# TM4C129ENCPDT register map
File version: 1.0
CPU: CORTEX_M4 1.0, other endian, MPU, FPU, 3 interrupt priority bits
Registers are 32-bit, read-write, reset 0x0 unless marked. A register's access mark holds for its fields unless they carry their own. Offsets are from the block's base; [hi:lo] are bit positions; {n}, {i} and the like mark numbered series.

## GPIO_PORTA_AHB — GPIO register offsets
Base 0x40058000
Same registers: GPIO_PORTB_AHB 0x40059000, GPIO_PORTC_AHB 0x4005A000, GPIO_PORTD_AHB 0x4005B000, GPIO_PORTE_AHB 0x4005C000, GPIO_PORTF_AHB 0x4005D000, GPIO_PORTG_AHB 0x4005E000, GPIO_PORTH_AHB 0x4005F000, GPIO_PORTJ_AHB 0x40060000, GPIO_PORTK 0x40061000, GPIO_PORTL 0x40062000, GPIO_PORTM 0x40063000, GPIO_PORTN 0x40064000, GPIO_PORTP 0x40065000, GPIO_PORTQ 0x40066000
0x3FC GPIO_DATA
0x400 GPIO_DIR — GPIO Direction
0x404 GPIO_IS — GPIO Interrupt Sense
0x408 GPIO_IBE — GPIO Interrupt Both Edges
0x40C GPIO_IEV — GPIO Interrupt Event
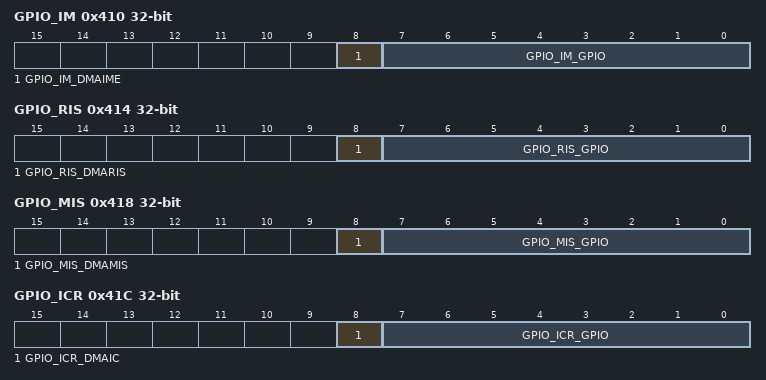
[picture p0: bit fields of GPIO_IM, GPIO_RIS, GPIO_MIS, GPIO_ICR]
0x410 GPIO_IM — GPIO Interrupt Mask
  [8] GPIO_IM_DMAIME — [8:8] GPIO uDMA Done Interrupt Mask Enable
  [7:0] GPIO_IM_GPIO — [7:0] GPIO Interrupt Mask Enable
0x414 GPIO_RIS — GPIO Raw Interrupt Status
  [8] GPIO_RIS_DMARIS — [8:8] GPIO uDMA Done Interrupt Raw Status
  [7:0] GPIO_RIS_GPIO — [7:0] GPIO Interrupt Raw Status
0x418 GPIO_MIS — GPIO Masked Interrupt Status
  [8] GPIO_MIS_DMAMIS — [8:8] GPIO uDMA Done Masked Interrupt Status
  [7:0] GPIO_MIS_GPIO — [7:0] GPIO Masked Interrupt Status
0x41C GPIO_ICR — GPIO Interrupt Clear
  [8] GPIO_ICR_DMAIC — [8:8] GPIO uDMA Interrupt Clear
  [7:0] GPIO_ICR_GPIO — [7:0] GPIO Interrupt Clear
0x420 GPIO_AFSEL — GPIO Alternate Function Select
0x500 GPIO_DR2R — GPIO 2-mA Drive Select
0x504 GPIO_DR4R — GPIO 4-mA Drive Select
0x508 GPIO_DR8R — GPIO 8-mA Drive Select
0x50C GPIO_ODR — GPIO Open Drain Select
0x510 GPIO_PUR — GPIO Pull-Up Select
0x514 GPIO_PDR — GPIO Pull-Down Select
0x518 GPIO_SLR — GPIO Slew Rate Control Select
0x51C GPIO_DEN — GPIO Digital Enable
0x520 GPIO_LOCK
  [31:0] GPIO_LOCK — [31:0] GPIO Lock
    0=GPIO_LOCK_UNLOCKED (The GPIOCR register is unlocked and may be modified); 1=GPIO_LOCK_LOCKED (The GPIOCR register is locked and may not be modified); 0x4C4F434B=GPIO_LOCK_KEY (Unlocks the GPIO_CR register)
0x524 GPIO_CR — GPIO Commit
0x528 GPIO_AMSEL — GPIO Analog Mode Select
0x52C GPIO_PCTL — GPIO Port Control
0x530 GPIO_ADCCTL — GPIO ADC Control
0x534 GPIO_DMACTL — GPIO DMA Control
0x538 GPIO_SI — GPIO Select Interrupt
  [0] GPIO_SI_SUM — [0:0] Summary Interrupt
0x53C GPIO_DR12R — GPIO 12-mA Drive Select
  [7:0] GPIO_DR12R_DRV12 — [7:0] Output Pad 12-mA Drive Enable
    1=GPIO_DR12R_DRV12_12MA (The corresponding GPIO pin has 12-mA drive. This encoding is only valid if the GPIOPP EDE bit is set and the appropriate GPIOPC EDM bit field is programmed to 0x3)
0x540 GPIO_WAKEPEN — GPIO Wake Pin Enable
  [4] GPIO_WAKEPEN_WAKEP4 — [4:4] P[4] Wake Enable
0x544 GPIO_WAKELVL — GPIO Wake Level
  [4] GPIO_WAKELVL_WAKELVL4 — [4:4] P[4] Wake Level
0x548 GPIO_WAKESTAT — GPIO Wake Status
  [4] GPIO_WAKESTAT_STAT4 — [4:4] P[4] Wake Status
0xFC0 GPIO_PP — GPIO Peripheral Property
  [0] GPIO_PP_EDE — [0:0] Extended Drive Enable
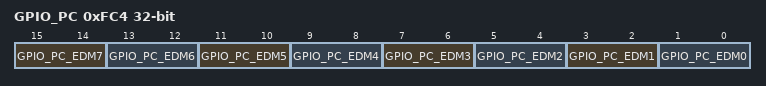
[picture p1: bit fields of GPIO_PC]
0xFC4 GPIO_PC — GPIO Peripheral Configuration
  [2n+1:2n] GPIO_PC_EDM{n} (n=1..7) — [{2n+1}:{2n}] Extended Drive Mode Bit {n}
  [1:0] GPIO_PC_EDM0 — [1:0] Extended Drive Mode Bit 0
    0=GPIO_PC_EDM0_DISABLE (Drive values of 2, 4 and 8 mA are maintained. GPIO n Drive Select (GPIODRnR) registers function as normal); 1=GPIO_PC_EDM0_6MA (An additional 6 mA option is provided); 3=GPIO_PC_EDM0_PLUS2MA (A 2 mA driver is always enabled; setting the corresponding GPIODR4R register bit adds 2 mA and setting the corresponding GPIODR8R of GPIODR12R register bit adds an additional 4 mA)

## EEPROM — EEPROM register offsets
Base 0x400AF000
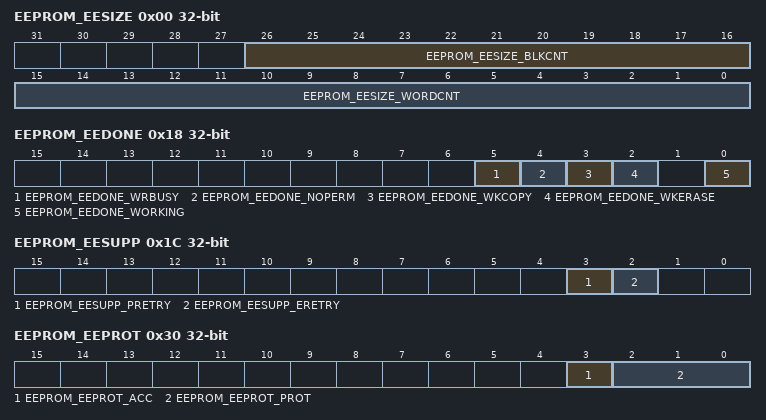
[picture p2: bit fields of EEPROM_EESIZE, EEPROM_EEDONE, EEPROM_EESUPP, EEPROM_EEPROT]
0x00 EEPROM_EESIZE — EEPROM Size Information
  [26:16] EEPROM_EESIZE_BLKCNT — [26:16] Number of 16-Word Blocks
  [15:0] EEPROM_EESIZE_WORDCNT — [15:0] Number of 32-Bit Words
0x04 EEPROM_EEBLOCK — EEPROM Current Block
  [15:0] EEPROM_EEBLOCK_BLOCK — [15:0] Current Block
0x08 EEPROM_EEOFFSET — EEPROM Current Offset
  [3:0] EEPROM_EEOFFSET_OFFSET — [3:0] Current Address Offset
0x10 EEPROM_EERDWR — EEPROM Read-Write
  [31:0] EEPROM_EERDWR_VALUE — [31:0] EEPROM Read or Write Data
0x14 EEPROM_EERDWRINC — EEPROM Read-Write with Increment
  [31:0] EEPROM_EERDWRINC_VALUE — [31:0] EEPROM Read or Write Data with Increment
0x18 EEPROM_EEDONE — EEPROM Done Status
  [5] EEPROM_EEDONE_WRBUSY — [5:5] Write Busy
  [4] EEPROM_EEDONE_NOPERM — [4:4] Write Without Permission
  [3] EEPROM_EEDONE_WKCOPY — [3:3] Working on a Copy
  [2] EEPROM_EEDONE_WKERASE — [2:2] Working on an Erase
  [0] EEPROM_EEDONE_WORKING — [0:0] EEPROM Working
0x1C EEPROM_EESUPP — EEPROM Support Control and Status
  [3] EEPROM_EESUPP_PRETRY — [3:3] Programming Must Be Retried
  [2] EEPROM_EESUPP_ERETRY — [2:2] Erase Must Be Retried
0x20 EEPROM_EEUNLOCK — EEPROM Unlock
  [31:0] EEPROM_EEUNLOCK_UNLOCK — [31:0] EEPROM Unlock
0x30 EEPROM_EEPROT — EEPROM Protection
  [3] EEPROM_EEPROT_ACC — [3:3] Access Control
  [2:0] EEPROM_EEPROT_PROT — [2:0] Protection Control
    0=EEPROM_EEPROT_PROT_RWNPW (This setting is the default. If there is no password, the block is not protected and is readable and writable); 1=EEPROM_EEPROT_PROT_RWPW (If there is a password, the block is readable or writable only when unlocked); 2=EEPROM_EEPROT_PROT_RONPW (If there is no password, the block is readable, not writable)
{0x34+4i} EEPROM_EEPASS{i} (i=0..2) — EEPROM Password
  [31:0] EEPROM_EEPASS{i}_PASS — [31:0] Password
0x40 EEPROM_EEINT — EEPROM Interrupt
  [0] EEPROM_EEINT_INT — [0:0] Interrupt Enable
0x50 EEPROM_EEHIDE0 — EEPROM Block Hide 0
  [31:1] EEPROM_EEHIDE0_HN — [31:1] Hide Block
0x54 EEPROM_EEHIDE1 — EEPROM Block Hide 1
  [31:0] EEPROM_EEHIDE1_HN — [31:0] Hide Block
0x58 EEPROM_EEHIDE2 — EEPROM Block Hide 2
  [31:0] EEPROM_EEHIDE2_HN — [31:0] Hide Block
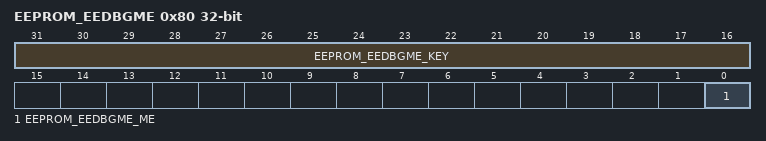
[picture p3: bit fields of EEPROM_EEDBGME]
0x80 EEPROM_EEDBGME — EEPROM Debug Mass Erase
  [31:16] EEPROM_EEDBGME_KEY — [31:16] Erase Key
  [0] EEPROM_EEDBGME_ME — [0:0] Mass Erase
0xFC0 EEPROM_PP — EEPROM Peripheral Properties
  [15:0] EEPROM_PP_SIZE — [15:0] EEPROM Size
    0=64 bytes of EEPROM; 1=128 bytes of EEPROM; 3=256 bytes of EEPROM; 7=512 bytes of EEPROM; 15=EEPROM_PP_SIZE_1K (1 KB of EEPROM); 31=EEPROM_PP_SIZE_2K (2 KB of EEPROM); 63=EEPROM_PP_SIZE_3K (3 KB of EEPROM); 127=EEPROM_PP_SIZE_4K (4 KB of EEPROM); 255=EEPROM_PP_SIZE_5K (5 KB of EEPROM); 0x1FF=EEPROM_PP_SIZE_6K (6 KB of EEPROM)
